# MK64F12 register map
Vendor: Freescale Semiconductor, Inc.; Series: Kinetis_K; File version: 1.6
CPU: CM4 r0p1, little endian, no MPU, FPU, VTOR, 4 interrupt priority bits
Registers are 32-bit, read-write, reset 0x0 unless marked. A register's access mark holds for its fields unless they carry their own. Offsets are from the block's base; [hi:lo] are bit positions; {n}, {i} and the like mark numbered series.

## DAC0 — 12-Bit Digital-to-Analog Converter
Base 0x400CC000; register names take the prefix DAC0_
{0x0+2i} DAT{i}L (i=0..15) 8-bit — DAC Data Low Register
  [7:0] DATA0 — When the DAC buffer is not enabled, DATA[11:0] controls the output voltage based on the following formula: V out = V in * (1 + DACDAT0[11:0])/4096 When the DAC buffer is enabled, DATA is mapped to the 16-word buffer
{0x1+2i} DAT{i}H (i=0..15) 8-bit — DAC Data High Register
  [3:0] DATA1 — When the DAC Buffer is not enabled, DATA[11:0] controls the output voltage based on the following formula
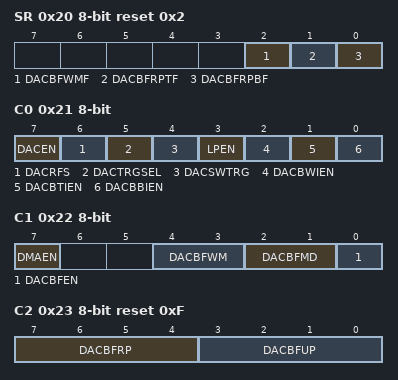
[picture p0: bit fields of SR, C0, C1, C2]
0x20 SR 8-bit reset 0x2 — DAC Status Register
  [2] DACBFWMF — DAC Buffer Watermark Flag
    0=The DAC buffer read pointer has not reached the watermark level; 1=The DAC buffer read pointer has reached the watermark level
  [1] DACBFRPTF — DAC Buffer Read Pointer Top Position Flag
    0=The DAC buffer read pointer is not zero; 1=The DAC buffer read pointer is zero
  [0] DACBFRPBF — DAC Buffer Read Pointer Bottom Position Flag
    0=The DAC buffer read pointer is not equal to C2[DACBFUP]; 1=The DAC buffer read pointer is equal to C2[DACBFUP]
0x21 C0 8-bit — DAC Control Register
  [7] DACEN — DAC Enable
    0=The DAC system is disabled; 1=The DAC system is enabled
  [6] DACRFS — DAC Reference Select
    0=The DAC selects DACREF_1 as the reference voltage; 1=The DAC selects DACREF_2 as the reference voltage
  [5] DACTRGSEL — DAC Trigger Select
    0=The DAC hardware trigger is selected; 1=The DAC software trigger is selected
  [4] DACSWTRG wo — DAC Software Trigger
    0=The DAC soft trigger is not valid; 1=The DAC soft trigger is valid
  [3] LPEN — DAC Low Power Control
    0=High-Power mode; 1=Low-Power mode
  [2] DACBWIEN — DAC Buffer Watermark Interrupt Enable
    0=The DAC buffer watermark interrupt is disabled; 1=The DAC buffer watermark interrupt is enabled
  [1] DACBTIEN — DAC Buffer Read Pointer Top Flag Interrupt Enable
    0=The DAC buffer read pointer top flag interrupt is disabled; 1=The DAC buffer read pointer top flag interrupt is enabled
  [0] DACBBIEN — DAC Buffer Read Pointer Bottom Flag Interrupt Enable
    0=The DAC buffer read pointer bottom flag interrupt is disabled; 1=The DAC buffer read pointer bottom flag interrupt is enabled
0x22 C1 8-bit — DAC Control Register 1
  [7] DMAEN — DMA Enable Select
    0=DMA is disabled; 1=DMA is enabled. When DMA is enabled, the DMA request will be generated by original interrupts. The interrupts will not be presented on this module at the same time.
  [4:3] DACBFWM — DAC Buffer Watermark Select
    0=1 word; 1=2 words; 2=3 words; 3=4 words
  [2:1] DACBFMD — DAC Buffer Work Mode Select
    0=Normal mode; 1=Swing mode; 2=One-Time Scan mode
  [0] DACBFEN — DAC Buffer Enable
    0=Buffer read pointer is disabled. The converted data is always the first word of the buffer.; 1=Buffer read pointer is enabled. The converted data is the word that the read pointer points to. It means converted data can be from any word of the buffer.
0x23 C2 8-bit reset 0xF — DAC Control Register 2
  [7:4] DACBFRP — DAC Buffer Read Pointer
  [3:0] DACBFUP — DAC Buffer Upper Limit

## DAC1 — 12-Bit Digital-to-Analog Converter
Base 0x400CD000; register names take the prefix DAC1_
Registers as DAC0.

## PTA — General Purpose Input/Output
Base 0x400FF000; register names take the prefix GPIOA_
0x00 PDOR — Port Data Output Register
  [31:0] PDO — Port Data Output
    0=Logic level 0 is driven on pin, provided pin is configured for general-purpose output; 1=Logic level 1 is driven on pin, provided pin is configured for general-purpose output
0x04 PSOR wo — Port Set Output Register
  [31:0] PTSO — Port Set Output
    0=Corresponding bit in PDORn does not change; 1=Corresponding bit in PDORn is set to logic 1
0x08 PCOR wo — Port Clear Output Register
  [31:0] PTCO — Port Clear Output
    0=Corresponding bit in PDORn does not change; 1=Corresponding bit in PDORn is cleared to logic 0
0x0C PTOR wo — Port Toggle Output Register
  [31:0] PTTO — Port Toggle Output
    0=Corresponding bit in PDORn does not change; 1=Corresponding bit in PDORn is set to the inverse of its existing logic state
0x10 PDIR ro — Port Data Input Register
  [31:0] PDI — Port Data Input
    0=Pin logic level is logic 0, or is not configured for use by digital function; 1=Pin logic level is logic 1
0x14 PDDR — Port Data Direction Register
  [31:0] PDD — Port Data Direction
    0=Pin is configured as general-purpose input, for the GPIO function; 1=Pin is configured as general-purpose output, for the GPIO function

## PTB — General Purpose Input/Output
Base 0x400FF040; register names take the prefix GPIOB_
Registers as PTA.

## PTC — General Purpose Input/Output
Base 0x400FF080; register names take the prefix GPIOC_
Registers as PTA; these are added or differ:
0x08 PCOR wo — Port Clear Output Register
  [31:0] PTCO — Port Clear Output
    0=Corresponding bit in PDORn does not change; 1=Corresponding bit in PDORn is cleared to logic 0

## PTD — General Purpose Input/Output
Base 0x400FF0C0; register names take the prefix GPIOD_
Registers as PTA.

## PTE — General Purpose Input/Output
Base 0x400FF100; register names take the prefix GPIOE_
Registers as PTA.

## Notices in the file
Redistribution and use in source and binary forms, with or without modification,
are permitted provided that the following conditions are met:
o Redistributions of source code must retain the above copyright notice, this list
of conditions and the following disclaimer.
o Redistributions in binary form must reproduce the above copyright notice, this
list of conditions and the following disclaimer in the documentation and/or
other materials provided with the distribution.
o Neither the name of Freescale Semiconductor, Inc. nor the names of its
contributors may be used to endorse or promote products derived from this
software without specific prior written permission.
THIS SOFTWARE IS PROVIDED BY THE COPYRIGHT HOLDERS AND CONTRIBUTORS "AS IS" AND
ANY EXPRESS OR IMPLIED WARRANTIES, INCLUDING, BUT NOT LIMITED TO, THE IMPLIED
WARRANTIES OF MERCHANTABILITY AND FITNESS FOR A PARTICULAR PURPOSE ARE
DISCLAIMED. IN NO EVENT SHALL THE COPYRIGHT HOLDER OR CONTRIBUTORS BE LIABLE FOR
ANY DIRECT, INDIRECT, INCIDENTAL, SPECIAL, EXEMPLARY, OR CONSEQUENTIAL DAMAGES
(INCLUDING, BUT NOT LIMITED TO, PROCUREMENT OF SUBSTITUTE GOODS OR SERVICES;
LOSS OF USE, DATA, OR PROFITS; OR BUSINESS INTERRUPTION) HOWEVER CAUSED AND ON
ANY THEORY OF LIABILITY, WHETHER IN CONTRACT, STRICT LIABILITY, OR TORT
(INCLUDING NEGLIGENCE OR OTHERWISE) ARISING IN ANY WAY OUT OF THE USE OF THIS
SOFTWARE, EVEN IF ADVISED OF THE POSSIBILITY OF SUCH DAMAGE.
